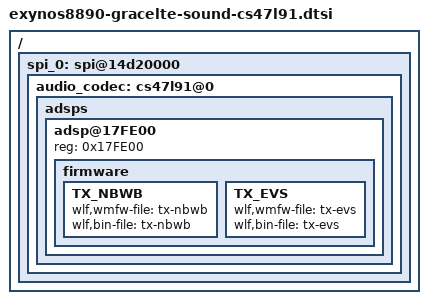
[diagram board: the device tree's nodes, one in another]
/*
 * SAMSUNG Grace-CS47L91 Sound Card Device Tree Source
 *
 * Copyright (c) 2016 Samsung Electronics Co., Ltd.
 *		http://www.samsung.com
 *
 * This program is free software; you can redistribute it and/or modify
 * it under the terms of the GNU General Public License version 2 as
 * published by the Free Software Foundation.
*/

/ {
	spi_0: spi@14d20000 {
		audio_codec: cs47l91@0 {
			adsps {
				adsp@17FE00 {
					reg = <0x17FE00>;
					firmware {
						TX_NBWB {
							wlf,wmfw-file = "tx-nbwb";
							wlf,bin-file = "tx-nbwb";
						};
						TX_EVS {
							wlf,wmfw-file = "tx-evs";
							wlf,bin-file = "tx-evs";
						};
					};
				};
			};
		};
	};
};
